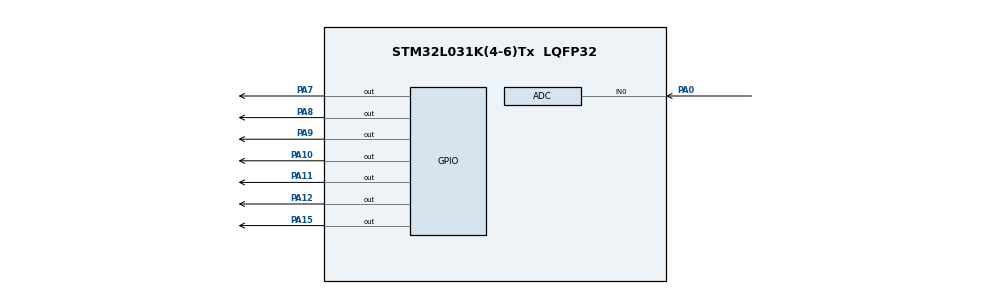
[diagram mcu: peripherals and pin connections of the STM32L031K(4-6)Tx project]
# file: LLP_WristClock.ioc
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Dma.ADC.0.Direction=DMA_PERIPH_TO_MEMORY
Dma.ADC.0.Instance=DMA1_Channel1
Dma.ADC.0.MemDataAlignment=DMA_MDATAALIGN_HALFWORD
Dma.ADC.0.MemInc=DMA_MINC_ENABLE
Dma.ADC.0.Mode=DMA_NORMAL
Dma.ADC.0.PeriphDataAlignment=DMA_PDATAALIGN_HALFWORD
Dma.ADC.0.PeriphInc=DMA_PINC_DISABLE
Dma.ADC.0.Priority=DMA_PRIORITY_LOW
Dma.Request0=ADC
Mcu.Family=STM32L0
Mcu.Name=STM32L031K(4-6)Tx
Mcu.Package=LQFP32
NVIC.DMA1_Channel1_IRQn=true\:0\:0\:false\:false\:true\:false\:true
PA0-CK_IN.Mode=IN0
PA0-CK_IN.Signal=ADC_IN0
PA10.Signal=GPIO_Output
PA11.Signal=GPIO_Output
PA12.Signal=GPIO_Output
PA15.Signal=GPIO_Output
PA7.Signal=GPIO_Output
PA8.Signal=GPIO_Output
PA9.Signal=GPIO_Output
ProjectManager.HeapSize=0x200
ProjectManager.StackSize=0x400
ProjectManager.TargetToolchain=STM32CubeIDE
RCC.AHBFreq_Value=2097000
RCC.APB1Freq_Value=2097000
RCC.APB1TimFreq_Value=2097000
RCC.APB2Freq_Value=2097000
RCC.APB2TimFreq_Value=2097000
RCC.HSE_VALUE=8000000
RCC.HSI16_VALUE=16000000
RCC.HSI_VALUE=16000000
RCC.LSE_VALUE=32768
RCC.MSI_VALUE=2097000
RCC.SYSCLKFreq_VALUE=2097000
RCC.VCOOutputFreq_Value=48000000
VP_RTC_VS_RTC_Activate.Mode=RTC_Enabled
VP_RTC_VS_RTC_Calendar.Mode=RTC_Calendar
board=custom

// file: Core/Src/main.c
/* USER CODE BEGIN Header */
/**
 ******************************************************************************
 * @file           : main.c
 * @brief          : Main program body
 ******************************************************************************
 * @attention
 *
 * <h2><center>&copy; Copyright (c) 2020 STMicroelectronics.
 * All rights reserved.</center></h2>
 *
 * This software component is licensed by ST under BSD 3-Clause license,
 * the "License"; You may not use this file except in compliance with the
 * License. You may obtain a copy of the License at:
 *                        opensource.org/licenses/BSD-3-Clause
 *
 ******************************************************************************
 */
/* USER CODE END Header */

#include "main.h"

/* USER CODE BEGIN Includes */

#include "BinaryWristWatch.h"
/* USER CODE END Includes */

/* USER CODE BEGIN PV */
uint8_t i = 0, j = 0; //for LED test purposes
uint32_t dumb_delay = 0; //for test purposes
extern uint32_t ms_counter;
/* USER CODE END PV */

void SystemClock_Config(void);
static void MX_GPIO_Init(void);
static void MX_DMA_Init(void);
static void MX_ADC_Init(void);
static void MX_RTC_Init(void);
//__STATIC_INLINE void LL_SYSTICK_SetClkSource(uint32_t);

int main(void) {

	/* MCU Configuration--------------------------------------------------------*/

	/* Reset of all peripherals, Initializes the Flash interface and the Systick. */

	LL_APB2_GRP1_EnableClock(LL_APB2_GRP1_PERIPH_SYSCFG);
	LL_APB1_GRP1_EnableClock(LL_APB1_GRP1_PERIPH_PWR);

	/* System interrupt init*/

	/* Configure the system clock */
	SystemClock_Config();

	/* Initialize all configured peripherals */
	//MX_GPIO_Init();
	LL_IOP_GRP1_EnableClock(LL_IOP_GRP1_PERIPH_GPIOA); //enable clock for GPIOA
	MX_DMA_Init();
	MX_ADC_Init();
	MX_RTC_Init();

	/* Infinite loop */
	/* USER CODE BEGIN WHILE */
	while (1) {

		if (ms_counter > 1000) //replace with systick
				{
			ms_counter=0;

			i++;
			if (i > 9) {
				i = 0;
				j++;
				if (j > 5) {
					j = 0;
				}
			}

		}
		set_lower_seconds(i);
		set_upper_seconds(j);

		/* USER CODE END WHILE */

	}
}

void SystemClock_Config(void) {
	LL_FLASH_SetLatency(LL_FLASH_LATENCY_0);

	if (LL_FLASH_GetLatency() != LL_FLASH_LATENCY_0) {
		Error_Handler();
	}
	LL_PWR_SetRegulVoltageScaling(LL_PWR_REGU_VOLTAGE_SCALE1);
	LL_RCC_LSI_Enable();

	/* Wait till LSI is ready */
	while (LL_RCC_LSI_IsReady() != 1) {

	}
	LL_RCC_MSI_Enable();

	/* Wait till MSI is ready */
	while (LL_RCC_MSI_IsReady() != 1) {

	}
	LL_RCC_MSI_SetRange(LL_RCC_MSIRANGE_5);
	LL_RCC_MSI_SetCalibTrimming(0);
	LL_PWR_EnableBkUpAccess();
	LL_RCC_ForceBackupDomainReset();
	LL_RCC_ReleaseBackupDomainReset();
	LL_RCC_SetRTCClockSource(LL_RCC_RTC_CLKSOURCE_LSI);
	LL_RCC_EnableRTC();
	LL_RCC_SetAHBPrescaler(LL_RCC_SYSCLK_DIV_1);
	LL_RCC_SetAPB1Prescaler(LL_RCC_APB1_DIV_1);
	LL_RCC_SetAPB2Prescaler(LL_RCC_APB2_DIV_1);
	LL_RCC_SetSysClkSource(LL_RCC_SYS_CLKSOURCE_MSI);

	/* Wait till System clock is ready */
	while (LL_RCC_GetSysClkSource() != LL_RCC_SYS_CLKSOURCE_STATUS_MSI) {

	}

	LL_Init1msTick(2097000);

	LL_SYSTICK_SetClkSource(LL_SYSTICK_CLKSOURCE_HCLK);
	LL_SetSystemCoreClock(2097000);

	/* SysTick_IRQn interrupt configuration */

	NVIC_SetPriority(SysTick_IRQn, 0);
	LL_SYSTICK_EnableIT();
}

static void MX_ADC_Init(void) {

	LL_ADC_REG_InitTypeDef ADC_REG_InitStruct = { 0 };
	LL_ADC_InitTypeDef ADC_InitStruct = { 0 };

	LL_GPIO_InitTypeDef GPIO_InitStruct = { 0 };

	/* Peripheral clock enable */
	LL_APB2_GRP1_EnableClock(LL_APB2_GRP1_PERIPH_ADC1);

	LL_IOP_GRP1_EnableClock(LL_IOP_GRP1_PERIPH_GPIOA);
	/**ADC GPIO Configuration
	 PA0-CK_IN   ------> ADC_IN0
	 */
	GPIO_InitStruct.Pin = LL_GPIO_PIN_0;
	GPIO_InitStruct.Mode = LL_GPIO_MODE_ANALOG;
	GPIO_InitStruct.Pull = LL_GPIO_PULL_NO;
	LL_GPIO_Init(GPIOA, &GPIO_InitStruct);

	/* ADC DMA Init */

	/* ADC Init */
	LL_DMA_SetPeriphRequest(DMA1, LL_DMA_CHANNEL_1, LL_DMA_REQUEST_0);

	LL_DMA_SetDataTransferDirection(DMA1, LL_DMA_CHANNEL_1,
	LL_DMA_DIRECTION_PERIPH_TO_MEMORY);

	LL_DMA_SetChannelPriorityLevel(DMA1, LL_DMA_CHANNEL_1, LL_DMA_PRIORITY_LOW);

	LL_DMA_SetMode(DMA1, LL_DMA_CHANNEL_1, LL_DMA_MODE_NORMAL);

	LL_DMA_SetPeriphIncMode(DMA1, LL_DMA_CHANNEL_1, LL_DMA_PERIPH_NOINCREMENT);

	LL_DMA_SetMemoryIncMode(DMA1, LL_DMA_CHANNEL_1, LL_DMA_MEMORY_INCREMENT);

	LL_DMA_SetPeriphSize(DMA1, LL_DMA_CHANNEL_1, LL_DMA_PDATAALIGN_HALFWORD);

	LL_DMA_SetMemorySize(DMA1, LL_DMA_CHANNEL_1, LL_DMA_MDATAALIGN_HALFWORD);

	/** Configure Regular Channel
	 */
	LL_ADC_REG_SetSequencerChAdd(ADC1, LL_ADC_CHANNEL_0);
	/** Common config
	 */
	ADC_REG_InitStruct.TriggerSource = LL_ADC_REG_TRIG_SOFTWARE;
	ADC_REG_InitStruct.SequencerDiscont = LL_ADC_REG_SEQ_DISCONT_DISABLE;
	ADC_REG_InitStruct.ContinuousMode = LL_ADC_REG_CONV_SINGLE;
	ADC_REG_InitStruct.DMATransfer = LL_ADC_REG_DMA_TRANSFER_LIMITED;
	ADC_REG_InitStruct.Overrun = LL_ADC_REG_OVR_DATA_PRESERVED;
	LL_ADC_REG_Init(ADC1, &ADC_REG_InitStruct);
	LL_ADC_SetSamplingTimeCommonChannels(ADC1, LL_ADC_SAMPLINGTIME_1CYCLE_5);
	LL_ADC_SetOverSamplingScope(ADC1, LL_ADC_OVS_DISABLE);
	LL_ADC_REG_SetSequencerScanDirection(ADC1, LL_ADC_REG_SEQ_SCAN_DIR_FORWARD);
	LL_ADC_SetCommonFrequencyMode(__LL_ADC_COMMON_INSTANCE(ADC1),
	LL_ADC_CLOCK_FREQ_MODE_HIGH);
	LL_ADC_DisableIT_EOC(ADC1);
	LL_ADC_DisableIT_EOS(ADC1);
	LL_ADC_EnableInternalRegulator(ADC1);
	ADC_InitStruct.Clock = LL_ADC_CLOCK_SYNC_PCLK_DIV1;
	ADC_InitStruct.Resolution = LL_ADC_RESOLUTION_12B;
	ADC_InitStruct.DataAlignment = LL_ADC_DATA_ALIGN_RIGHT;
	ADC_InitStruct.LowPowerMode = LL_ADC_LP_MODE_NONE;
	LL_ADC_Init(ADC1, &ADC_InitStruct);

}

static void MX_RTC_Init(void) {

	LL_RTC_InitTypeDef RTC_InitStruct = { 0 };
	LL_RTC_TimeTypeDef RTC_TimeStruct = { 0 };
	LL_RTC_DateTypeDef RTC_DateStruct = { 0 };

	/* Peripheral clock enable */
	LL_RCC_EnableRTC();

	/** Initialize RTC and set the Time and Date
	 */
	RTC_InitStruct.HourFormat = LL_RTC_HOURFORMAT_24HOUR;
	RTC_InitStruct.AsynchPrescaler = 127;
	RTC_InitStruct.SynchPrescaler = 255;
	LL_RTC_Init(RTC, &RTC_InitStruct);
	/** Initialize RTC and set the Time and Date
	 */
	RTC_TimeStruct.Hours = 0;
	RTC_TimeStruct.Minutes = 0;
	RTC_TimeStruct.Seconds = 0;
	LL_RTC_TIME_Init(RTC, LL_RTC_FORMAT_BCD, &RTC_TimeStruct);
	RTC_DateStruct.WeekDay = LL_RTC_WEEKDAY_MONDAY;
	RTC_DateStruct.Month = LL_RTC_MONTH_JANUARY;
	RTC_DateStruct.Year = 0;
	LL_RTC_DATE_Init(RTC, LL_RTC_FORMAT_BCD, &RTC_DateStruct);

}

static void MX_DMA_Init(void) {

	/* Init with LL driver */
	/* DMA controller clock enable */
	LL_AHB1_GRP1_EnableClock(LL_AHB1_GRP1_PERIPH_DMA1);

	/* DMA interrupt init */
	/* DMA1_Channel1_IRQn interrupt configuration */
	NVIC_SetPriority(DMA1_Channel1_IRQn, 0);
	NVIC_EnableIRQ(DMA1_Channel1_IRQn);

}

static void MX_GPIO_Init(void) {
	LL_GPIO_InitTypeDef GPIO_InitStruct = { 0 };

	/* GPIO Ports Clock Enable */
	LL_IOP_GRP1_EnableClock(LL_IOP_GRP1_PERIPH_GPIOA);

	/**/
	LL_GPIO_ResetOutputPin(GPIOA, LL_GPIO_PIN_7);

	/**/
	LL_GPIO_ResetOutputPin(GPIOA, LL_GPIO_PIN_8);

	/**/
	LL_GPIO_ResetOutputPin(GPIOA, LL_GPIO_PIN_9);

	/**/
	LL_GPIO_ResetOutputPin(GPIOA, LL_GPIO_PIN_10);

	/**/
	LL_GPIO_ResetOutputPin(GPIOA, LL_GPIO_PIN_11);

	/**/
	LL_GPIO_ResetOutputPin(GPIOA, LL_GPIO_PIN_12);

	/**/
	LL_GPIO_ResetOutputPin(GPIOA, LL_GPIO_PIN_15);

	/**/
	GPIO_InitStruct.Pin = LL_GPIO_PIN_7;
	GPIO_InitStruct.Mode = LL_GPIO_MODE_OUTPUT;
	GPIO_InitStruct.Speed = LL_GPIO_SPEED_FREQ_LOW;
	GPIO_InitStruct.OutputType = LL_GPIO_OUTPUT_PUSHPULL;
	GPIO_InitStruct.Pull = LL_GPIO_PULL_NO;
	LL_GPIO_Init(GPIOA, &GPIO_InitStruct);

	/**/
	GPIO_InitStruct.Pin = LL_GPIO_PIN_8;
	GPIO_InitStruct.Mode = LL_GPIO_MODE_OUTPUT;
	GPIO_InitStruct.Speed = LL_GPIO_SPEED_FREQ_LOW;
	GPIO_InitStruct.OutputType = LL_GPIO_OUTPUT_PUSHPULL;
	GPIO_InitStruct.Pull = LL_GPIO_PULL_NO;
	LL_GPIO_Init(GPIOA, &GPIO_InitStruct);

	/**/
	GPIO_InitStruct.Pin = LL_GPIO_PIN_9;
	GPIO_InitStruct.Mode = LL_GPIO_MODE_OUTPUT;
	GPIO_InitStruct.Speed = LL_GPIO_SPEED_FREQ_LOW;
	GPIO_InitStruct.OutputType = LL_GPIO_OUTPUT_PUSHPULL;
	GPIO_InitStruct.Pull = LL_GPIO_PULL_NO;
	LL_GPIO_Init(GPIOA, &GPIO_InitStruct);

	/**/
	GPIO_InitStruct.Pin = LL_GPIO_PIN_10;
	GPIO_InitStruct.Mode = LL_GPIO_MODE_OUTPUT;
	GPIO_InitStruct.Speed = LL_GPIO_SPEED_FREQ_LOW;
	GPIO_InitStruct.OutputType = LL_GPIO_OUTPUT_PUSHPULL;
	GPIO_InitStruct.Pull = LL_GPIO_PULL_NO;
	LL_GPIO_Init(GPIOA, &GPIO_InitStruct);

	/**/
	GPIO_InitStruct.Pin = LL_GPIO_PIN_11;
	GPIO_InitStruct.Mode = LL_GPIO_MODE_OUTPUT;
	GPIO_InitStruct.Speed = LL_GPIO_SPEED_FREQ_LOW;
	GPIO_InitStruct.OutputType = LL_GPIO_OUTPUT_PUSHPULL;
	GPIO_InitStruct.Pull = LL_GPIO_PULL_NO;
	LL_GPIO_Init(GPIOA, &GPIO_InitStruct);

	/**/
	GPIO_InitStruct.Pin = LL_GPIO_PIN_12;
	GPIO_InitStruct.Mode = LL_GPIO_MODE_OUTPUT;
	GPIO_InitStruct.Speed = LL_GPIO_SPEED_FREQ_LOW;
	GPIO_InitStruct.OutputType = LL_GPIO_OUTPUT_PUSHPULL;
	GPIO_InitStruct.Pull = LL_GPIO_PULL_NO;
	LL_GPIO_Init(GPIOA, &GPIO_InitStruct);

	/**/
	GPIO_InitStruct.Pin = LL_GPIO_PIN_15;
	GPIO_InitStruct.Mode = LL_GPIO_MODE_OUTPUT;
	GPIO_InitStruct.Speed = LL_GPIO_SPEED_FREQ_LOW;
	GPIO_InitStruct.OutputType = LL_GPIO_OUTPUT_PUSHPULL;
	GPIO_InitStruct.Pull = LL_GPIO_PULL_NO;
	LL_GPIO_Init(GPIOA, &GPIO_InitStruct);

}

void Error_Handler(void) {
}

/************************ (C) COPYRIGHT STMicroelectronics *****END OF FILE****/
